# ioqn9020 register map
Registers from a debugger description file.
Registers are 32-bit, access not given, no defined reset value unless marked. A register's access mark holds for its fields unless they carry their own. Addresses are absolute; registers are grouped by the start of their names; lines under a group give offsets from that group; [hi:lo] are bit positions; {n}, {i} and the like mark numbered series; 'fields as' and 'values as' point back to an identical list; <NAME> marks a mode.

## Further device data
interrupts=NMI 0x08; HardFault 0x0C; MemManage 0x10; BusFault 0x14; UsageFault 0x18; SVC 0x2C; DebugMon 0x30; PendSV 0x38; SysTick 0x3C; GPIO 0x40; COMPARATOR1 0x44; COMPARATOR2 0x48; BLE 0x4C; RTC_CAP 0x50; OSC_EN 0x54; RTC 0x58; ADC 0x5C; DMA 0x60; UART0_TX 0x68; UART0_RX 0x6C; SPI0_TX 0x70; SPI0_RX 0x74; UART1_TX 0x78; UART1_RX 0x7C; SPI1_TX 0x80; SPI1_RX 0x84; I2C 0x88; TIMER0 0x8C; TIMER1 0x90; TIMER2 0x94; TIMER3 0x98; WDT 0x9C; PWM0 0xA0; PWM1 0xA4; CALIB 0xA8

## SFR
0x3FFFFFF0 SFCMD1ADDR3
0x3FFFFFF4 SFCMD1
0x3FFFFFF8 SFDATA_LEN
0x3FFFFFFC SFCTRL_STAT
0x4000000C SYS_TICK_CTRL
0x40000010 BOOT_MODE_CTRL
0x40000014 SRAM_OTP_CTRL
0x40000038 RST_CAUSE_SRC
0x4000003C IO_WAKEUP_CTRL
0x40000040 BLE_STATUS
0x40000080 SCAN_BIST_TEST
0x40000088 CHIP_ID
0x4000009C GAIN_CTRL
0x400000A0 IVREF_BUCK
0x400000A4 XTAL_REF
0x400000A8 LO1
0x400000AC LO2
0x400000B0 RX_CTRL
0x400000B4 SAR_ADC_CTRL
0x40001000 WDTLOAD
0x40001004 WDTVALUE
0x40001008 WDTCTRL
0x4000100C WDTINTCLR
0x40001010 WDTRAWINTSTAT
0x40001014 WDTMASKINTSTAT
0x40001C00 WDTLOCK
0x40001F00 WDTITCR
0x40001F04 WDTITOP
{0x40002000+0x1000*i} TMR{i}TCR (i=0..3)
{0x40002004+0x1000*i} TMR{i}IFR (i=0..3)
{0x40002008+0x1000*i} TMR{i}TOPR (i=0..3)
{0x4000200C+0x1000*i} TMR{i}ICER (i=0..3)
{0x40002010+0x1000*i} TMR{i}CCR (i=0..3)
{0x40002014+0x1000*i} TMR{i}TCNT (i=0..3)
0x40007000 UART0TXD
0x40007004 UART0RXD
0x40007008 UART0BAUD
0x4000700C UART0CR
0x40007010 UART0FLAG
0x40007800 SPI0CTRL0
0x40007804 SPI0CTRL1
0x40007810 SPI0TXD
0x40007814 SPI0RXD
0x40007818 SPI0STAT
0x40007A00 SPI1CTRL0
0x40007A04 SPI1CTRL1
0x40007A10 SPI1TXD
0x40007A14 SPI1RXD
0x40007A18 SPI1STAT
0x40008000 I2CCTRL
0x40008000 RTCCTRL
0x40008004 I2CSTAT
0x40008004 RTCSTATUS
0x40008008 I2CTXD
0x40008008 RTCSEC
0x4000800C I2CRXD
0x4000800C RTCCORR
0x40008010 I2CINT
0x40008010 RTCCALIB
0x40008014 RTCCNT
0x40009000 DMASRC_ADDR
0x40009004 DMADST_ADDR
0x40009008 DMACTRL
0x4000900C DMAABORT
0x40009010 DMASTATUS
0x4000A000 UART1TXD
0x4000A004 UART1RXD
0x4000A008 UART1BAUD
0x4000A00C UART1CR
0x4000A010 UART1FLAG
{0x4000C000+4i} CAL{i} (i=0..3)
0x4000C010 CALCR
0x4000C014 CALSR
0x4000E000 PWMCTRL
0x4000E004 PWMPSCL
0x4000E008 PWMPCP
0x4000E00C PWMSR
0x50000000 DATA
0x50000004 DATAOUT
0x50000010 OUTENABLESET
0x50000014 OUTENABLECLR
0x50000020 INTENSET
0x50000024 INTENCLR
0x50000028 INTTYPESET
0x5000002C INTTYPECLR
0x50000030 INTPOLSET
0x50000034 INTPOLCLR
0x50000038 INTSTATUS
0x50000038 INTCLEAR
{0x50010000+4i} ADC{i} (i=0..3)
0x50010010 ADCSR
0x50010014 ADCDATA
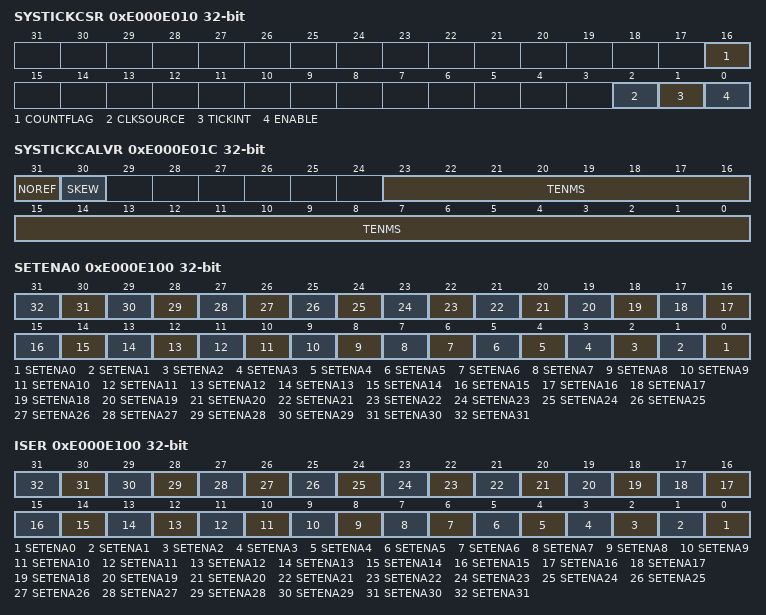
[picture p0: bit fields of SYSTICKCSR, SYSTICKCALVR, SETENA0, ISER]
0xE000E010 SYSTICKCSR
  [16] COUNTFLAG, [2] CLKSOURCE, [1] TICKINT, [0] ENABLE
0xE000E014 SYSTICKRVR
  [23:0] RELOAD
0xE000E018 SYSTICKCVR
  [23:0] CURRENT
0xE000E01C SYSTICKCALVR
  [31] NOREF, [30] SKEW, [23:0] TENMS
0xE000E100 SETENA0
  [n] SETENA{n} (n=0..31)
0xE000E100 ISER
  [n] SETENA{n} (n=0..31)
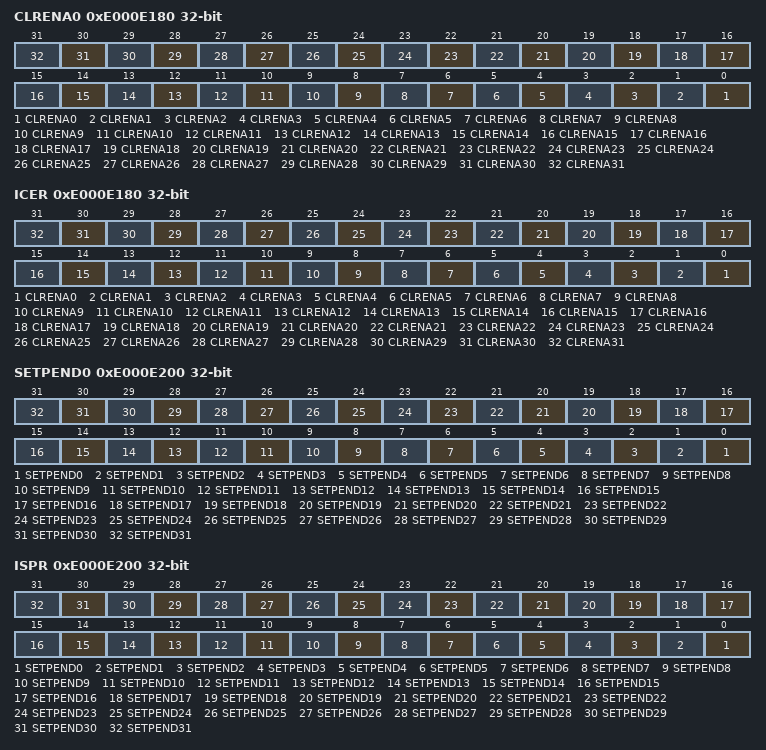
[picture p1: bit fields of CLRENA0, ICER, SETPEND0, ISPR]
0xE000E180 CLRENA0
  [n] CLRENA{n} (n=0..31)
0xE000E180 ICER
  [n] CLRENA{n} (n=0..31)
0xE000E200 SETPEND0
  [n] SETPEND{n} (n=0..31)
0xE000E200 ISPR
  [n] SETPEND{n} (n=0..31)
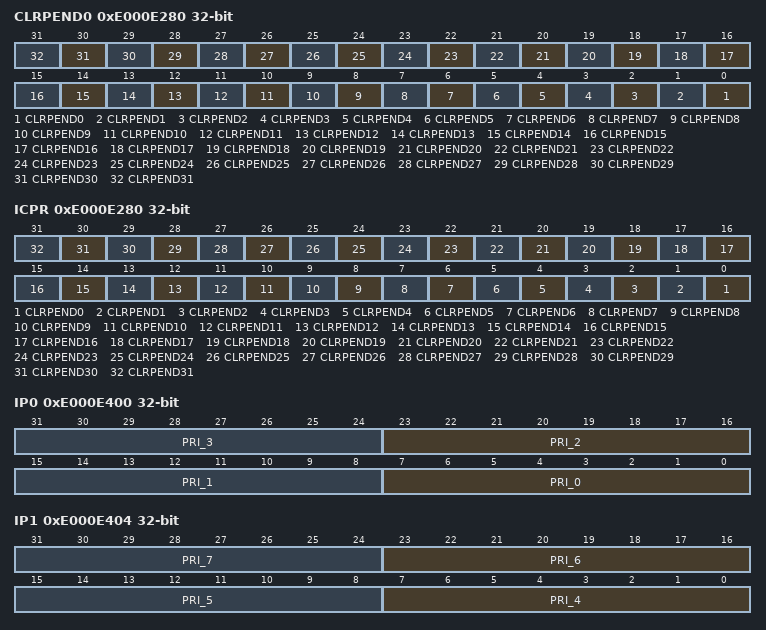
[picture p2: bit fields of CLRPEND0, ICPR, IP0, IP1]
0xE000E280 CLRPEND0
  [n] CLRPEND{n} (n=0..31)
0xE000E280 ICPR
  [n] CLRPEND{n} (n=0..31)
0xE000E400 IP0
  [8n+7:8n] PRI_{n} (n=0..3)
0xE000E404 IP1
  [8n-25:8n-32] PRI_{n} (n=4..7)
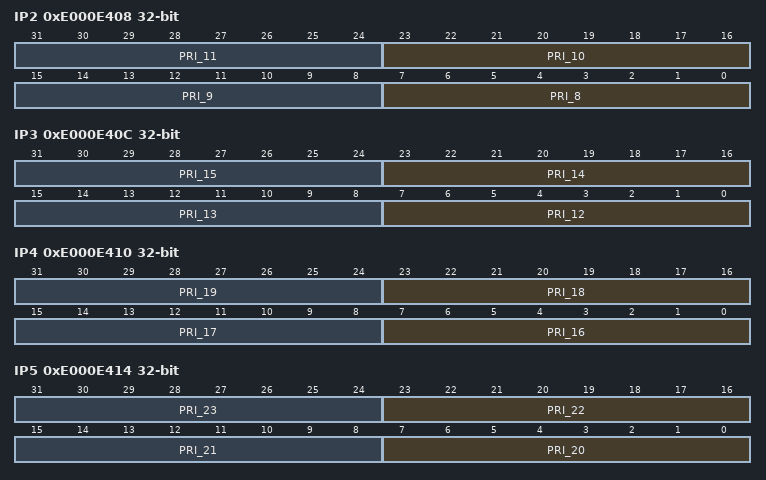
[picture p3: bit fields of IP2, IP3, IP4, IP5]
0xE000E408 IP2
  [8n-57:8n-64] PRI_{n} (n=8..11)
0xE000E40C IP3
  [8n-89:8n-96] PRI_{n} (n=12..15)
0xE000E410 IP4
  [8n-121:8n-128] PRI_{n} (n=16..19)
0xE000E414 IP5
  [8n-153:8n-160] PRI_{n} (n=20..23)
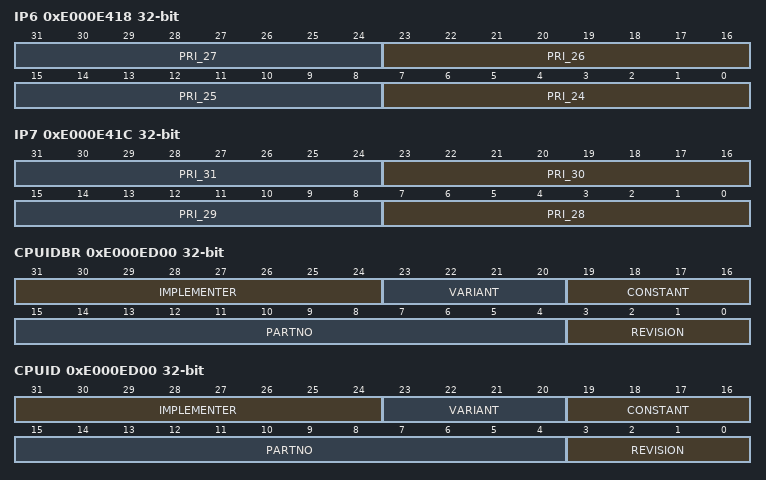
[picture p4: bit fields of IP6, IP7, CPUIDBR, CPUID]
0xE000E418 IP6
  [8n-185:8n-192] PRI_{n} (n=24..27)
0xE000E41C IP7
  [8n-217:8n-224] PRI_{n} (n=28..31)
0xE000ED00 CPUIDBR
  [31:24] IMPLEMENTER, [23:20] VARIANT, [19:16] CONSTANT, [15:4] PARTNO, [3:0] REVISION
0xE000ED00 CPUID
  fields as CPUIDBR
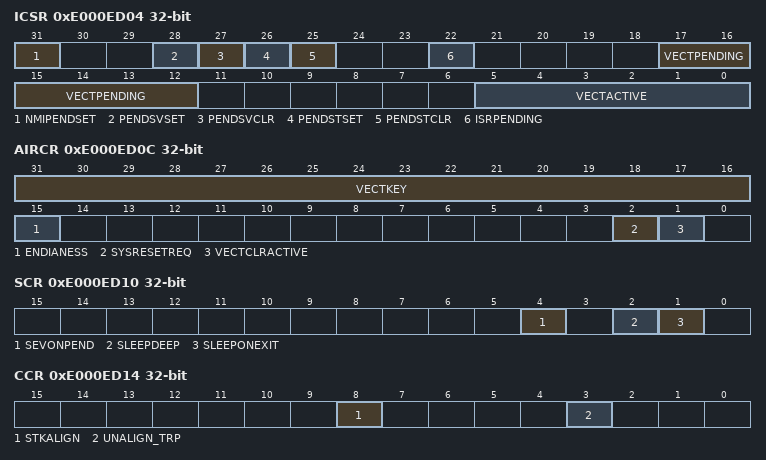
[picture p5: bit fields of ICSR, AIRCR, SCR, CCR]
0xE000ED04 ICSR
  [31] NMIPENDSET, [28] PENDSVSET, [27] PENDSVCLR, [26] PENDSTSET, [25] PENDSTCLR, [22] ISRPENDING, [17:12] VECTPENDING, [5:0] VECTACTIVE
0xE000ED0C AIRCR
  [31:16] VECTKEY, [15] ENDIANESS, [2] SYSRESETREQ, [1] VECTCLRACTIVE
0xE000ED10 SCR
  [4] SEVONPEND, [2] SLEEPDEEP, [1] SLEEPONEXIT
0xE000ED14 CCR
  [8] STKALIGN, [3] UNALIGN_TRP
0xE000ED1C SHPR2
  [31:24] PRI_11
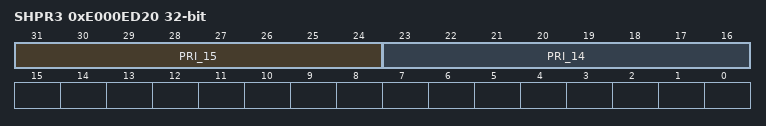
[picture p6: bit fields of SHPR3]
0xE000ED20 SHPR3
  [31:24] PRI_15, [23:16] PRI_14

## CLK
0x40000000 CLK_RST_SOFT_SET
0x40000004 CLK_RST_SOFT_CLR
0x40000008 CLK_MUX_DIV_CTRL

## PIN
{0x40000020+4i} PIN_MUX_CTRL{i} (i=0..2)

## PAD
0x4000002C PAD_DRV_CTRL
0x40000030 PAD_PULL_CTRL0
0x40000034 PAD_PULL_CTRL1

## POWER
{0x40000090+4i} POWER_GATING_CTRL{i} (i=0..2)

## SPI0BUF
0x40007808 SPI0BUF_PTR
0x4000780C SPI0BUF_STAT

## SPI1BUF
0x40007A08 SPI1BUF_PTR
0x40007A0C SPI1BUF_STAT

## SFFLASH
0x3FFFFFE8 SFFLASH_ID
0x3FFFFFEC SFFLASH_SR
